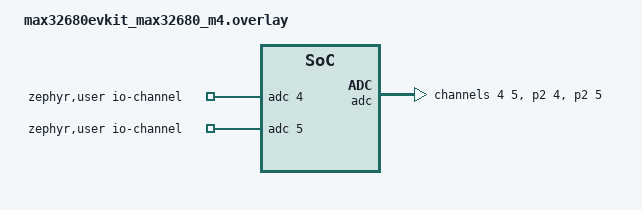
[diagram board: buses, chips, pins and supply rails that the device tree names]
/*
 * Copyright (c) 2024 Analog Devices, Inc.
 *
 * SPDX-License-Identifier: Apache-2.0
 */

/ {
	zephyr,user {
		/* adjust channel number according to pinmux in board.dts */
		io-channels = <&adc 4>, <&adc 5>;
	};
};

&adc {
	status = "okay";
	pinctrl-0 = <&ain12_p2_4 &ain13_p2_5>;
	pinctrl-names = "default";
	#address-cells = <1>;
	#size-cells = <0>;

	channel@4 {
		reg = <4>;
		zephyr,gain = "ADC_GAIN_1";
		zephyr,reference = "ADC_REF_INTERNAL";
		zephyr,acquisition-time = <ADC_ACQ_TIME_DEFAULT>;
		zephyr,resolution = <10>;
	};

	channel@5 {
		reg = <5>;
		zephyr,gain = "ADC_GAIN_1";
		zephyr,reference = "ADC_REF_INTERNAL";
		zephyr,acquisition-time = <ADC_ACQ_TIME_DEFAULT>;
		zephyr,resolution = <10>;
	};
};
